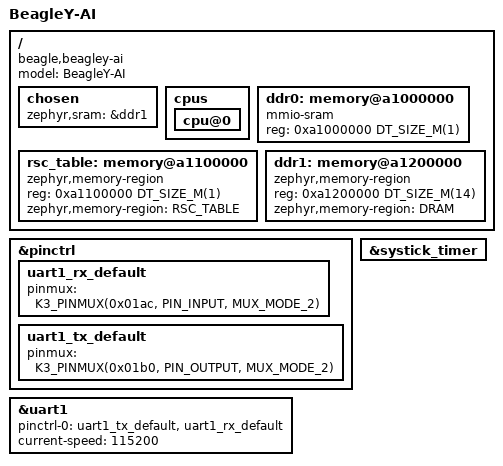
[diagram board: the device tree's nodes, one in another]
/*
 * Copyright (c) 2024 Texas Instruments Incorporated
 *	Andrew Davis <afd@ti.com>
 *
 * SPDX-License-Identifier: Apache-2.0
 */

/dts-v1/;

#include <ti/j722s_r5_mcu.dtsi>
#include <zephyr/dt-bindings/pinctrl/ti-k3-pinctrl.h>
#include <freq.h>

/ {
	model = "BeagleY-AI";
	compatible = "beagle,beagley-ai";

	chosen {
		zephyr,sram = &ddr1;
//		zephyr,console = &uart1;
//		zephyr,shell-uart = &uart1;
	};

	cpus {
		cpu@0 {
			status = "okay";
		};
	};

	ddr0: memory@a1000000 {
		compatible = "mmio-sram";
		reg = <0xa1000000 DT_SIZE_M(1)>;
	};

	rsc_table: memory@a1100000 {
		compatible = "zephyr,memory-region", "mmio-sram";
		reg = <0xa1100000 DT_SIZE_M(1)>;
		zephyr,memory-region = "RSC_TABLE";
	};

	ddr1: memory@a1200000 {
		compatible = "zephyr,memory-region", "mmio-sram";
		reg = <0xa1200000 DT_SIZE_M(14)>;
		zephyr,memory-region = "DRAM";
	};
};

&pinctrl {
	uart1_rx_default: uart1_rx_default {
		pinmux = <K3_PINMUX(0x01ac, PIN_INPUT, MUX_MODE_2)>; /* (C27) MCASP0_AFSR.UART1_RXD */
	};

	uart1_tx_default: uart1_tx_default {
		pinmux = <K3_PINMUX(0x01b0, PIN_OUTPUT, MUX_MODE_2)>; /* (F24) MCASP0_ACLKR.UART1_TXD */
	};
};

&uart1 {
//	status = "okay";
	pinctrl-0 = <&uart1_tx_default &uart1_rx_default>;
	pinctrl-names = "default";
	current-speed = <115200>;
};

&systick_timer {
	status = "okay";
};
